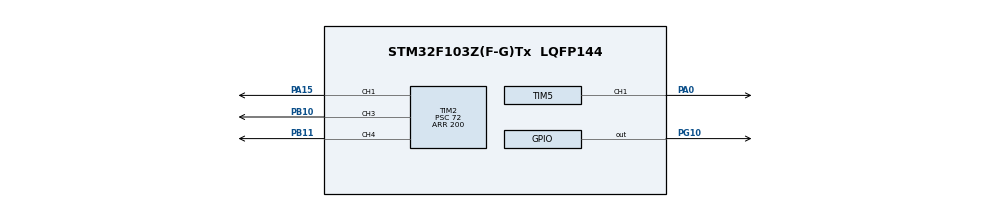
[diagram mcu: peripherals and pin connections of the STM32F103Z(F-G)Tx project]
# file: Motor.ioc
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Mcu.Family=STM32F1
Mcu.Name=STM32F103Z(F-G)Tx
Mcu.Package=LQFP144
NVIC.PriorityGroup=NVIC_PRIORITYGROUP_4
PA0-WKUP.Signal=S_TIM5_CH1
PA13.Mode=Serial_Wire
PA13.Signal=SYS_JTMS-SWDIO
PA14.Mode=Serial_Wire
PA14.Signal=SYS_JTCK-SWCLK
PA15.Signal=S_TIM2_CH1_ETR
PB10.Signal=S_TIM2_CH3
PB11.Signal=S_TIM2_CH4
PG10.Signal=GPIO_Output
ProjectManager.HeapSize=0x200
ProjectManager.StackSize=0x400
ProjectManager.TargetToolchain=MDK-ARM V5.27
RCC.APB1Freq_Value=8000000
RCC.APB2Freq_Value=8000000
SH.S_TIM2_CH1_ETR.0=TIM2_CH1,PWM Generation1 CH1
SH.S_TIM2_CH3.0=TIM2_CH3,PWM Generation3 CH3
SH.S_TIM2_CH4.0=TIM2_CH4,PWM Generation4 CH4
SH.S_TIM5_CH1.0=TIM5_CH1,PWM Generation1 CH1
TIM2.Channel-PWM\ Generation1\ CH1=TIM_CHANNEL_1
TIM2.Channel-PWM\ Generation3\ CH3=TIM_CHANNEL_3
TIM2.Channel-PWM\ Generation4\ CH4=TIM_CHANNEL_4
TIM2.Period=200
TIM2.Prescaler=72
TIM5.Channel-PWM\ Generation1\ CH1=TIM_CHANNEL_1
TIM5.Period=200
TIM5.Prescaler=72
board=custom

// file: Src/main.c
/* USER CODE BEGIN Header */
/**
  ******************************************************************************
  * @file           : main.c
  * @brief          : Main program body
  ******************************************************************************
  * @attention
  *
  * <h2><center>&copy; Copyright (c) 2019 STMicroelectronics.
  * All rights reserved.</center></h2>
  *
  * This software component is licensed by ST under BSD 3-Clause license,
  * the "License"; You may not use this file except in compliance with the
  * License. You may obtain a copy of the License at:
  *                        opensource.org/licenses/BSD-3-Clause
  *
  ******************************************************************************
  */
/* USER CODE END Header */

#include "main.h"

TIM_HandleTypeDef htim2;
TIM_HandleTypeDef htim5;

void SystemClock_Config(void);
static void MX_GPIO_Init(void);
static void MX_TIM2_Init(void);
static void MX_TIM5_Init(void);

int main(void)
{

  /* MCU Configuration--------------------------------------------------------*/

  /* Reset of all peripherals, Initializes the Flash interface and the Systick. */
  HAL_Init();

  /* Configure the system clock */
  SystemClock_Config();

  /* Initialize all configured peripherals */
  MX_GPIO_Init();
  MX_TIM2_Init();
  MX_TIM5_Init();
  /* USER CODE BEGIN 2 */
  // Setup DC PWM
  HAL_TIM_PWM_Start(&htim5, TIM_CHANNEL_1);
  HAL_TIMEx_PWMN_Start(&htim5, TIM_CHANNEL_1);
  __HAL_TIM_SET_COMPARE(&htim5, TIM_CHANNEL_1, 100);
  /* USER CODE END 2 */

  /* Infinite loop */
  /* USER CODE BEGIN WHILE */
  while (1)
  {
    // Toggle DC enable
	  HAL_GPIO_TogglePin(GPIOG, GPIO_PIN_10);

    // Delay 1sec
	  HAL_Delay(1000);
    /* USER CODE END WHILE */

  }
}

void SystemClock_Config(void)
{
  RCC_OscInitTypeDef RCC_OscInitStruct = {0};
  RCC_ClkInitTypeDef RCC_ClkInitStruct = {0};

  /** Initializes the CPU, AHB and APB busses clocks
  */
  RCC_OscInitStruct.OscillatorType = RCC_OSCILLATORTYPE_HSI;
  RCC_OscInitStruct.HSIState = RCC_HSI_ON;
  RCC_OscInitStruct.HSICalibrationValue = RCC_HSICALIBRATION_DEFAULT;
  RCC_OscInitStruct.PLL.PLLState = RCC_PLL_NONE;
  if (HAL_RCC_OscConfig(&RCC_OscInitStruct) != HAL_OK)
  {
    Error_Handler();
  }
  /** Initializes the CPU, AHB and APB busses clocks
  */
  RCC_ClkInitStruct.ClockType = RCC_CLOCKTYPE_HCLK|RCC_CLOCKTYPE_SYSCLK
                              |RCC_CLOCKTYPE_PCLK1|RCC_CLOCKTYPE_PCLK2;
  RCC_ClkInitStruct.SYSCLKSource = RCC_SYSCLKSOURCE_HSI;
  RCC_ClkInitStruct.AHBCLKDivider = RCC_SYSCLK_DIV1;
  RCC_ClkInitStruct.APB1CLKDivider = RCC_HCLK_DIV1;
  RCC_ClkInitStruct.APB2CLKDivider = RCC_HCLK_DIV1;

  if (HAL_RCC_ClockConfig(&RCC_ClkInitStruct, FLASH_LATENCY_0) != HAL_OK)
  {
    Error_Handler();
  }
}

static void MX_TIM2_Init(void)
{

  TIM_MasterConfigTypeDef sMasterConfig = {0};
  TIM_OC_InitTypeDef sConfigOC = {0};

  htim2.Instance = TIM2;
  htim2.Init.Prescaler = 72;
  htim2.Init.CounterMode = TIM_COUNTERMODE_UP;
  htim2.Init.Period = 200;
  htim2.Init.ClockDivision = TIM_CLOCKDIVISION_DIV1;
  htim2.Init.AutoReloadPreload = TIM_AUTORELOAD_PRELOAD_DISABLE;
  if (HAL_TIM_PWM_Init(&htim2) != HAL_OK)
  {
    Error_Handler();
  }
  sMasterConfig.MasterOutputTrigger = TIM_TRGO_RESET;
  sMasterConfig.MasterSlaveMode = TIM_MASTERSLAVEMODE_DISABLE;
  if (HAL_TIMEx_MasterConfigSynchronization(&htim2, &sMasterConfig) != HAL_OK)
  {
    Error_Handler();
  }
  sConfigOC.OCMode = TIM_OCMODE_PWM1;
  sConfigOC.Pulse = 0;
  sConfigOC.OCPolarity = TIM_OCPOLARITY_HIGH;
  sConfigOC.OCFastMode = TIM_OCFAST_DISABLE;
  if (HAL_TIM_PWM_ConfigChannel(&htim2, &sConfigOC, TIM_CHANNEL_1) != HAL_OK)
  {
    Error_Handler();
  }
  if (HAL_TIM_PWM_ConfigChannel(&htim2, &sConfigOC, TIM_CHANNEL_3) != HAL_OK)
  {
    Error_Handler();
  }
  if (HAL_TIM_PWM_ConfigChannel(&htim2, &sConfigOC, TIM_CHANNEL_4) != HAL_OK)
  {
    Error_Handler();
  }
  HAL_TIM_MspPostInit(&htim2);

}

static void MX_TIM5_Init(void)
{

  TIM_MasterConfigTypeDef sMasterConfig = {0};
  TIM_OC_InitTypeDef sConfigOC = {0};

  htim5.Instance = TIM5;
  htim5.Init.Prescaler = 72;
  htim5.Init.CounterMode = TIM_COUNTERMODE_UP;
  htim5.Init.Period = 200;
  htim5.Init.ClockDivision = TIM_CLOCKDIVISION_DIV1;
  htim5.Init.AutoReloadPreload = TIM_AUTORELOAD_PRELOAD_DISABLE;
  if (HAL_TIM_PWM_Init(&htim5) != HAL_OK)
  {
    Error_Handler();
  }
  sMasterConfig.MasterOutputTrigger = TIM_TRGO_RESET;
  sMasterConfig.MasterSlaveMode = TIM_MASTERSLAVEMODE_DISABLE;
  if (HAL_TIMEx_MasterConfigSynchronization(&htim5, &sMasterConfig) != HAL_OK)
  {
    Error_Handler();
  }
  sConfigOC.OCMode = TIM_OCMODE_PWM1;
  sConfigOC.Pulse = 0;
  sConfigOC.OCPolarity = TIM_OCPOLARITY_HIGH;
  sConfigOC.OCFastMode = TIM_OCFAST_DISABLE;
  if (HAL_TIM_PWM_ConfigChannel(&htim5, &sConfigOC, TIM_CHANNEL_1) != HAL_OK)
  {
    Error_Handler();
  }
  HAL_TIM_MspPostInit(&htim5);

}

static void MX_GPIO_Init(void)
{
  GPIO_InitTypeDef GPIO_InitStruct = {0};

  /* GPIO Ports Clock Enable */
  __HAL_RCC_GPIOA_CLK_ENABLE();
  __HAL_RCC_GPIOB_CLK_ENABLE();
  __HAL_RCC_GPIOG_CLK_ENABLE();

  /*Configure GPIO pin Output Level */
  HAL_GPIO_WritePin(GPIOG, GPIO_PIN_10, GPIO_PIN_RESET);

  /*Configure GPIO pin : PG10 */
  GPIO_InitStruct.Pin = GPIO_PIN_10;
  GPIO_InitStruct.Mode = GPIO_MODE_OUTPUT_PP;
  GPIO_InitStruct.Pull = GPIO_NOPULL;
  GPIO_InitStruct.Speed = GPIO_SPEED_FREQ_LOW;
  HAL_GPIO_Init(GPIOG, &GPIO_InitStruct);

}

void Error_Handler(void)
{
}

/************************ (C) COPYRIGHT STMicroelectronics *****END OF FILE****/
